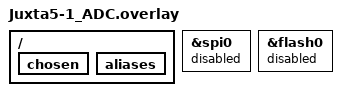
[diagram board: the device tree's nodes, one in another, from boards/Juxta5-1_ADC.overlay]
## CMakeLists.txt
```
#-------------------------------------------------------------------------------
# JUXTA BLE Application
#
# Copyright (c) 2024 NeurotechHub
# SPDX-License-Identifier: Apache-2.0

cmake_minimum_required(VERSION 3.20.0)

find_package(Zephyr REQUIRED HINTS $ENV{ZEPHYR_BASE})
project(juxta_ble LANGUAGES C)

target_sources(app PRIVATE
    src/main.c
    src/ble_service.c
    src/lis2dh12.c
)

# Add include directories for our libraries
target_include_directories(app PRIVATE 
    ../../lib/juxta_vitals_nrf52/include
    ../../lib/juxta_framfs/include
    ../../lib/juxta_fram/include
    ../../lib/lisd2h12
)

# Add library source files directly
target_sources(app PRIVATE 
    ../../lib/juxta_vitals_nrf52/src/vitals.c
    ../../lib/juxta_framfs/src/framfs.c
    ../../lib/juxta_fram/src/fram.c
    ../../lib/lisd2h12/lis2dh12_reg.c
) 
```

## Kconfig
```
# JUXTA BLE Application Configuration
#
# Copyright (c) 2024 NeurotechHub
# SPDX-License-Identifier: Apache-2.0

menu "JUXTA BLE Application"

config JUXTA_BLE_RANDOMIZATION
	bool "Enable randomization for BLE operations"
	default y
	help
	  Enable randomization for BLE advertising and scanning intervals
	  to reduce collision probability in dense deployments.

config JUXTA_BLE_MOTION_GATING
	bool "Enable motion-based BLE gating"
	default y
	help
	  Enable motion-based gating that adjusts BLE intervals based on
	  motion activity to save power.

endmenu

# Include Zephyr Kconfig
source "Kconfig.zephyr"

# Include library Kconfig files
rsource "../../lib/juxta_vitals_nrf52/Kconfig"
rsource "../../lib/juxta_fram/Kconfig"
rsource "../../lib/juxta_framfs/Kconfig" 
```

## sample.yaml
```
# Configuration file for nRF Connect SDK and testing tools
sample:
  description: Juxta BLE Application with LED Control
  name: juxta-ble
common:
  build_only: true
  integration_platforms:
    - nrf52dk_nrf52832
tests:
  app.default: {}
```

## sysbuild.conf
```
# Enable MCUboot for testing minimal configuration
SB_CONFIG_BOOTLOADER_MCUBOOT=y
```

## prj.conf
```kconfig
# Basic Bluetooth configuration - using observer architecture
CONFIG_BT=y
CONFIG_BT_OBSERVER=y
CONFIG_BT_PERIPHERAL=y
CONFIG_BT_DEVICE_NAME="JX_CONNECT"
CONFIG_BT_DEVICE_NAME_DYNAMIC=y
CONFIG_BT_MAX_CONN=1

# Enable maximum BLE GATT MTU for efficient file transfer.
# Actual ATT_MTU is negotiated at runtime by the peer (e.g., mobile app).
# NOTE: ACL buffers must be larger than L2CAP MTU to accommodate ATT headers
# Conservative approach: Use smaller buffers to avoid memory issues
CONFIG_BT_L2CAP_TX_MTU=247
CONFIG_BT_BUF_ACL_RX_SIZE=251
CONFIG_BT_BUF_ACL_TX_SIZE=251

# Additional BLE stack configuration for stability
CONFIG_BT_CTLR=y
CONFIG_BT_CTLR_ADV_EXT=n
CONFIG_BT_CTLR_SCAN_REQ_NOTIFY=n
CONFIG_BT_CTLR_SCAN_REQ_RSSI=n
CONFIG_BT_CTLR_ADV_INDICATION=n

# CONFIG_BT_CTLR_TX_PWR_PLUS_4=y
# CONFIG_BT_CTLR_TX_PWR_MINUS_8=y

# Counter API for nRF52 - DISABLED due to BLE conflict
# CONFIG_COUNTER=y
# CONFIG_NRFX_RTC0=y

# Random number generation
CONFIG_ENTROPY_GENERATOR=y

# RTT Configuration for debugging
CONFIG_USE_SEGGER_RTT=y
CONFIG_RTT_CONSOLE=y
CONFIG_SEGGER_RTT_BUFFER_SIZE_UP=8192
CONFIG_SEGGER_RTT_BUFFER_SIZE_DOWN=32

# Memory settings (increased for stability)
CONFIG_SYSTEM_WORKQUEUE_STACK_SIZE=2048
CONFIG_MAIN_STACK_SIZE=2048
CONFIG_ISR_STACK_SIZE=2048
CONFIG_BT_RX_STACK_SIZE=2048
CONFIG_BT_HCI_TX_STACK_SIZE=1536

# Minimal Bluetooth features
CONFIG_BT_SMP=n
CONFIG_BT_SIGNING=n
CONFIG_BT_ATT_PREPARE_COUNT=0
CONFIG_BT_PRIVACY=n
CONFIG_BT_SETTINGS=n
CONFIG_BT_BUF_EVT_RX_COUNT=2
CONFIG_BT_BUF_EVT_DISCARDABLE_COUNT=2

# Basic logging
CONFIG_LOG=y
CONFIG_LOG_DEFAULT_LEVEL=3
CONFIG_CONSOLE=y
CONFIG_LOG_BACKEND_RTT=y

# Enable drivers needed by vitals library and future FRAM integration
CONFIG_SPI=y
CONFIG_SPI_NRFX=y
CONFIG_ADC=y
CONFIG_ADC_ASYNC=y

# LIS2DH12 Accelerometer support - using custom driver
# CONFIG_SENSOR=y  # Disabled - using custom LIS2DH12 driver
# CONFIG_LIS2DH=y  # Disabled - using custom LIS2DH12 driver
# CONFIG_SPI_LOG_LEVEL_DBG=y
# CONFIG_SENSOR_LOG_LEVEL_DBG=y

# JUXTA Libraries
CONFIG_JUXTA_VITALS_NRF52=y
CONFIG_JUXTA_FRAM=y
CONFIG_JUXTA_FRAMFS=y

# Disable unused drivers
CONFIG_I2C=n

# Compiler optimizations
CONFIG_SIZE_OPTIMIZATIONS=y
CONFIG_COMPILER_OPT="-Os"

# Reduce kernel features
# CONFIG_MINIMAL_LIBC=y 
CONFIG_NEWLIB_LIBC=y
CONFIG_NEWLIB_LIBC_FLOAT_PRINTF=y
CONFIG_NEWLIB_LIBC_FLOAT_SCANF=y 

# Enable better fault context and debugging
CONFIG_DEBUG_THREAD_INFO=y
CONFIG_ASSERT=y 

CONFIG_THREAD_STACK_INFO=y
CONFIG_HW_STACK_PROTECTION=y

# Watchdog timer for system reliability
CONFIG_WATCHDOG=y
# Driver will be selected automatically for nRF; keep this if needed in this NCS version
CONFIG_WDT_NRFX=y

# SMP/MCUmgr over BLE (no MCUboot yet) per SMP.md
CONFIG_SETTINGS=y
CONFIG_BT_SETTINGS=y

CONFIG_MCUMGR=y
CONFIG_MCUMGR_TRANSPORT_BT=y
CONFIG_MCUMGR_GRP_IMG=y
CONFIG_MCUMGR_GRP_OS=y
CONFIG_IMG_MANAGER=y
CONFIG_STREAM_FLASH=y
CONFIG_ZCBOR=y
CONFIG_FLASH=y
CONFIG_FLASH_MAP=y
CONFIG_PARTITION_MANAGER_ENABLED=y

# Enable MCUboot bootloader with Partition Manager (per SMP.md)
CONFIG_BOOTLOADER_MCUBOOT=y

# Pull in Nordic sample DFU defaults to resolve upload area and related settings
CONFIG_NCS_SAMPLE_MCUMGR_BT_OTA_DFU=y

CONFIG_NRFX_SAADC=y
CONFIG_NRFX_TIMER1=y
CONFIG_NRFX_PPI=y

# Power Management Configuration
CONFIG_PM=y
CONFIG_PM_DEVICE=y
CONFIG_PM_DEVICE_RUNTIME=y

# Note: The brownout threshold is configured at the hardware level
# through the POWER module registers in main.c runtime configuration.
```

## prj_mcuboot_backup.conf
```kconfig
# Basic Bluetooth configuration - using observer architecture
CONFIG_BT=y
CONFIG_BT_OBSERVER=y
CONFIG_BT_PERIPHERAL=y
CONFIG_BT_DEVICE_NAME="JX_CONNECT"
CONFIG_BT_DEVICE_NAME_DYNAMIC=n
CONFIG_BT_MAX_CONN=1

# Enable maximum BLE GATT MTU (247 bytes) for efficient file transfer.
# Actual ATT_MTU is negotiated at runtime by the peer (e.g., mobile app).
CONFIG_BT_L2CAP_TX_MTU=247
CONFIG_BT_BUF_ACL_RX_SIZE=251
CONFIG_BT_BUF_ACL_TX_SIZE=251

# Additional BLE stack configuration for stability
# CONFIG_BT_CTLR=y  # Deprecated - controller is auto-selected
CONFIG_BT_CTLR_ADV_EXT=n
CONFIG_BT_CTLR_SCAN_REQ_NOTIFY=n
CONFIG_BT_CTLR_SCAN_REQ_RSSI=n
CONFIG_BT_CTLR_ADV_INDICATION=n

# Enable maximum BLE transmit power (+4 dBm) for extended range
CONFIG_BT_CTLR_TX_PWR_PLUS_4=y

# Counter API for nRF52 - DISABLED due to BLE conflict
# CONFIG_COUNTER=y
# CONFIG_NRFX_RTC0=y

# Random number generation
CONFIG_ENTROPY_GENERATOR=y

# RTT Configuration for debugging
CONFIG_USE_SEGGER_RTT=y
CONFIG_RTT_CONSOLE=y
CONFIG_SEGGER_RTT_BUFFER_SIZE_UP=8192
CONFIG_SEGGER_RTT_BUFFER_SIZE_DOWN=32

# Memory settings (increased for stability)
CONFIG_SYSTEM_WORKQUEUE_STACK_SIZE=2048
CONFIG_MAIN_STACK_SIZE=2048
CONFIG_ISR_STACK_SIZE=2048
CONFIG_BT_RX_STACK_SIZE=2048
CONFIG_BT_HCI_TX_STACK_SIZE=1536

# Minimal Bluetooth features
CONFIG_BT_SMP=n
CONFIG_BT_SIGNING=n
CONFIG_BT_ATT_PREPARE_COUNT=0
CONFIG_BT_PRIVACY=n
CONFIG_BT_SETTINGS=n
CONFIG_BT_BUF_EVT_RX_COUNT=2
CONFIG_BT_BUF_EVT_DISCARDABLE_COUNT=2

# Basic logging
CONFIG_LOG=y
CONFIG_LOG_DEFAULT_LEVEL=3
CONFIG_CONSOLE=y
CONFIG_LOG_BACKEND_RTT=y

# Enable drivers needed by vitals library and future FRAM integration
CONFIG_SPI=y
CONFIG_SPI_NRFX=y
CONFIG_ADC=y

# LIS2DH12 Accelerometer support - using custom driver
# CONFIG_SENSOR=y  # Disabled - using custom LIS2DH12 driver
# CONFIG_LIS2DH=y  # Disabled - using custom LIS2DH12 driver
# CONFIG_SPI_LOG_LEVEL_DBG=y
# CONFIG_SENSOR_LOG_LEVEL_DBG=y

# JUXTA Libraries
CONFIG_JUXTA_VITALS_NRF52=y
CONFIG_JUXTA_FRAM=y
CONFIG_JUXTA_FRAMFS=y

# Disable unused drivers
CONFIG_I2C=n

# Compiler optimizations
CONFIG_SIZE_OPTIMIZATIONS=y
CONFIG_COMPILER_OPT="-Os"

# Reduce kernel features
# CONFIG_MINIMAL_LIBC=y 
CONFIG_NEWLIB_LIBC=y
CONFIG_NEWLIB_LIBC_FLOAT_PRINTF=y
CONFIG_NEWLIB_LIBC_FLOAT_SCANF=y 

# Enable better fault context and debugging
CONFIG_DEBUG_THREAD_INFO=y
CONFIG_ASSERT=y 

CONFIG_THREAD_STACK_INFO=y
CONFIG_HW_STACK_PROTECTION=y

# Watchdog timer for system reliability
CONFIG_WATCHDOG=y
# Driver will be selected automatically for nRF; keep this if needed in this NCS version
CONFIG_WDT_NRFX=y

# SMP/MCUmgr over BLE (no MCUboot yet) per SMP.md
CONFIG_SETTINGS=y
CONFIG_BT_SETTINGS=y

CONFIG_MCUMGR=y
CONFIG_MCUMGR_TRANSPORT_BT=y
CONFIG_MCUMGR_GRP_IMG=y
CONFIG_MCUMGR_GRP_OS=y
CONFIG_IMG_MANAGER=y
CONFIG_STREAM_FLASH=y
CONFIG_ZCBOR=y
CONFIG_FLASH=y
CONFIG_FLASH_MAP=y

# Enable MCUboot bootloader with fixed partitions
CONFIG_BOOTLOADER_MCUBOOT=y

# Ensure proper vector table relocation for MCUboot slot0 (0x10000)
CONFIG_USE_DT_CODE_PARTITION=y

# Pull in Nordic sample DFU defaults to resolve upload area and related settings
CONFIG_NCS_SAMPLE_MCUMGR_BT_OTA_DFU=y
```

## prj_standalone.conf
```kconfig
# Temporary standalone test - copy of prj.conf but without MCUboot
# Basic Bluetooth configuration - using observer architecture
CONFIG_BT=y
CONFIG_BT_OBSERVER=y
CONFIG_BT_PERIPHERAL=y
CONFIG_BT_DEVICE_NAME="JX_CONNECT"
CONFIG_BT_DEVICE_NAME_DYNAMIC=n
CONFIG_BT_MAX_CONN=1

# Enable maximum BLE GATT MTU (247 bytes) for efficient file transfer.
# Actual ATT_MTU is negotiated at runtime by the peer (e.g., mobile app).
CONFIG_BT_L2CAP_TX_MTU=247
CONFIG_BT_BUF_ACL_RX_SIZE=251
CONFIG_BT_BUF_ACL_TX_SIZE=251

# Additional BLE stack configuration for stability
# CONFIG_BT_CTLR=y  # Deprecated - controller is auto-selected
CONFIG_BT_CTLR_ADV_EXT=n
CONFIG_BT_CTLR_SCAN_REQ_NOTIFY=n
CONFIG_BT_CTLR_SCAN_REQ_RSSI=n
CONFIG_BT_CTLR_ADV_INDICATION=n

# Enable maximum BLE transmit power (+4 dBm) for extended range
CONFIG_BT_CTLR_TX_PWR_PLUS_4=y

# Counter API for nRF52 - DISABLED due to BLE conflict
# CONFIG_COUNTER=y
# CONFIG_NRFX_RTC0=y

# Random number generation
CONFIG_ENTROPY_GENERATOR=y

# RTT Configuration for debugging
CONFIG_USE_SEGGER_RTT=y
CONFIG_RTT_CONSOLE=y
CONFIG_SEGGER_RTT_BUFFER_SIZE_UP=8192
CONFIG_SEGGER_RTT_BUFFER_SIZE_DOWN=32

# Memory settings (increased for stability)
CONFIG_SYSTEM_WORKQUEUE_STACK_SIZE=2048
CONFIG_MAIN_STACK_SIZE=2048
CONFIG_ISR_STACK_SIZE=2048
CONFIG_BT_RX_STACK_SIZE=2048
CONFIG_BT_HCI_TX_STACK_SIZE=1536

# Minimal Bluetooth features
CONFIG_BT_SMP=n
CONFIG_BT_SIGNING=n
CONFIG_BT_ATT_PREPARE_COUNT=0
CONFIG_BT_PRIVACY=n
CONFIG_BT_SETTINGS=n
CONFIG_BT_BUF_EVT_RX_COUNT=2
CONFIG_BT_BUF_EVT_DISCARDABLE_COUNT=2

# Basic logging
CONFIG_LOG=y
CONFIG_LOG_DEFAULT_LEVEL=3
CONFIG_CONSOLE=y
CONFIG_LOG_BACKEND_RTT=y

# Enable drivers needed by vitals library and future FRAM integration
CONFIG_SPI=y
CONFIG_SPI_NRFX=y
CONFIG_ADC=y

# JUXTA Libraries
CONFIG_JUXTA_VITALS_NRF52=y
CONFIG_JUXTA_FRAM=y
CONFIG_JUXTA_FRAMFS=y

# Disable unused drivers
CONFIG_I2C=n

# Compiler optimizations
CONFIG_SIZE_OPTIMIZATIONS=y
CONFIG_COMPILER_OPT="-Os"

# Reduce kernel features
# CONFIG_MINIMAL_LIBC=y 
CONFIG_NEWLIB_LIBC=y
CONFIG_NEWLIB_LIBC_FLOAT_PRINTF=y
CONFIG_NEWLIB_LIBC_FLOAT_SCANF=y 

# Enable better fault context and debugging
CONFIG_DEBUG_THREAD_INFO=y
CONFIG_ASSERT=y 

CONFIG_THREAD_STACK_INFO=y
CONFIG_HW_STACK_PROTECTION=y

# Watchdog timer for system reliability
CONFIG_WATCHDOG=y
# Driver will be selected automatically for nRF; keep this if needed in this NCS version
CONFIG_WDT_NRFX=y

# NO MCUboot - standalone test
# CONFIG_BOOTLOADER_MCUBOOT=n
```

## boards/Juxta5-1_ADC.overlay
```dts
/*
 * Device tree overlay for Juxta BLE application
 * Disables SPI/FRAM functionality since this app only needs BLE and LED
 */

/ {
    chosen {
        /delete-property/ zephyr,eeprom;
    };

    aliases {
        /delete-property/ spi-fram;
    };
};

&spi0 {
    status = "disabled";

    /delete-node/ fram@0;
};

&flash0 {
    status = "disabled";
}; 
```

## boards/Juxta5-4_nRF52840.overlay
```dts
/*
 * Board overlay for Juxta5-4_nRF52840 for BLE application
 * This file configures the board for BLE and RTC functionality
 */

/ {
    aliases {
        rtc = &rtc0;
    };
};

/* Configure RTC for timestamp management */
&rtc0 {
    status = "okay";
    clock-frequency = <32768>;
    interrupt-parent = <&nvic>;
    interrupts = <11 NRF_DEFAULT_IRQ_PRIORITY>;
}; 
```

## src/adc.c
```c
/*
 * JUXTA ADC Module Implementation
 * Provides functionality for reading differential ADC measurements
 *
 * Copyright (c) 2025 NeurotechHub
 * SPDX-License-Identifier: Apache-2.0
 */

#include "adc.h"
#include <zephyr/drivers/adc.h>
#include <zephyr/logging/log.h>
#include <zephyr/devicetree.h>
#include <zephyr/irq.h>
#include <string.h>
#include <math.h>
#include <hal/nrf_rtc.h>
#include <hal/nrf_saadc.h>

LOG_MODULE_REGISTER(juxta_adc, LOG_LEVEL_INF);

/* ADC device and configuration */
static const struct device *adc_dev;
static struct adc_channel_cfg adc_cfg;
static struct adc_sequence adc_seq;
static int16_t adc_sample_buffer;
static bool adc_initialized = false;

int juxta_adc_init(void)
{
    int ret;

    /* Get ADC device */
    adc_dev = DEVICE_DT_GET(DT_NODELABEL(adc));
    if (!device_is_ready(adc_dev))
    {
        LOG_ERR("ADC device not ready");
        return -ENODEV;
    }

    LOG_INF("ADC device ready: %s", adc_dev->name);

    /* Configure ADC channel 0 for differential measurement (AIN0/AIN1) */
    memset(&adc_cfg, 0, sizeof(adc_cfg));
    adc_cfg.gain = ADC_GAIN_1_6;
    adc_cfg.reference = ADC_REF_INTERNAL;
    adc_cfg.acquisition_time = ADC_ACQ_TIME_DEFAULT;
    adc_cfg.channel_id = 0;                                     /* Use channel 0 for differential measurement */
    adc_cfg.input_positive = SAADC_CH_PSELP_PSELP_AnalogInput1; /* P0.03 */
    adc_cfg.input_negative = SAADC_CH_PSELN_PSELN_AnalogInput0; /* P0.02 */
    adc_cfg.differential = 1;

    ret = adc_channel_setup(adc_dev, &adc_cfg);
    if (ret != 0)
    {
        LOG_ERR("Failed to setup ADC channel: %d", ret);
        return ret;
    }

    /* Configure ADC sequence */
    memset(&adc_seq, 0, sizeof(adc_seq));
    adc_seq.channels = BIT(0);
    adc_seq.buffer = &adc_sample_buffer;
    adc_seq.buffer_size = sizeof(adc_sample_buffer);
    adc_seq.resolution = 12;
    adc_seq.oversampling = 0; /* Disable oversampling for maximum speed */
    adc_seq.calibrate = true;

    LOG_INF("ADC differential measurement configured:");
    LOG_INF("  Channel: %d", adc_cfg.channel_id);
    LOG_INF("  Input: AIN1 (P0.03) - AIN0 (P0.02)");
    LOG_INF("  Resolution: %d bits", adc_seq.resolution);
    LOG_INF("  Oversampling: %d", adc_seq.oversampling);
    LOG_INF("  Gain: 1/6");

    adc_initialized = true;
    return 0;
}

int juxta_adc_read_differential(int32_t *value_mv)
{
    int ret;

    if (!adc_initialized || !adc_dev)
    {
        LOG_ERR("ADC not initialized");
        return -ENODEV;
    }

    if (!value_mv)
    {
        LOG_ERR("Invalid parameter: value_mv is NULL");
        return -EINVAL;
    }

    /* Read ADC value */
    ret = adc_read(adc_dev, &adc_seq);
    if (ret != 0)
    {
        LOG_ERR("ADC read failed: %d", ret);
        return ret;
    }

    LOG_DBG("ADC raw value: %d", adc_sample_buffer);

    /* Convert to millivolts */
    *value_mv = adc_sample_buffer;
    ret = adc_raw_to_millivolts(adc_ref_internal(adc_dev),
                                adc_cfg.gain,
                                adc_seq.resolution,
                                value_mv);
    if (ret != 0)
    {
        LOG_ERR("ADC conversion failed: %d", ret);
        return ret;
    }

    LOG_DBG("ADC differential reading: %d mV (raw: %d)", *value_mv, adc_sample_buffer);
    return 0;
}

bool juxta_adc_is_ready(void)
{
    return adc_initialized && device_is_ready(adc_dev);
}

int juxta_adc_burst_sample(int32_t *samples, uint32_t max_samples,
                           uint32_t *actual_samples, uint32_t *duration_us)
{
    if (!adc_initialized || !adc_dev)
    {
        return -ENODEV;
    }

    if (!samples || !actual_samples || !duration_us)
    {
        return -EINVAL;
    }

    if (max_samples < 100)
    {
        return -EINVAL;
    }

    /* Start timing using RTC0 counter (32kHz clock) */
    uint32_t start_ticks = NRF_RTC0->COUNTER;
    uint32_t sample_count = 0;

    /* Debug: Log RTC0 configuration for timing verification */
    LOG_DBG("🔍 RTC0 Debug: PRESCALER=0x%08X, COUNTER=%u, start_ticks=%u",
            (unsigned)NRF_RTC0->PRESCALER, (unsigned)NRF_RTC0->COUNTER, (unsigned)start_ticks);

    /* Use optimized batch sampling to avoid per-sample overhead */
    /* Configure sequence for burst sampling */
    static int16_t burst_buffer[500]; /* Static buffer for raw ADC values */

    struct adc_sequence burst_seq = {
        .channels = BIT(0),
        .buffer = burst_buffer,
        .buffer_size = sizeof(burst_buffer),
        .resolution = 12,
        .oversampling = 0, /* Disable oversampling for maximum speed */
        .calibrate = false /* Disable per-read calibration for speed */
    };

    /* Disable interrupts during critical sampling for consistent timing */
    unsigned int key = irq_lock();

    /* Perform optimized burst sampling with minimal overhead */
    for (uint32_t i = 0; i < max_samples; i++)
    {
        /* Direct ADC read without function call overhead */
        int ret = adc_read(adc_dev, &burst_seq);

        if (ret == 0)
        {
            /* Convert raw ADC value to millivolts */
            int32_t voltage_mv = burst_buffer[0];
            ret = adc_raw_to_millivolts(adc_ref_internal(adc_dev),
                                        adc_cfg.gain,
                                        burst_seq.resolution,
                                        &voltage_mv);

            samples[sample_count] = (ret == 0) ? voltage_mv : 0;
            sample_count++;
        }
        else
        {
            /* Use previous sample value if ADC read fails */
            if (sample_count > 0)
            {
                samples[sample_count] = samples[sample_count - 1];
            }
            else
            {
                samples[sample_count] = 0; /* Default to 0 if no previous sample */
            }
            sample_count++;
        }

        /* No artificial delay - let ADC conversion time be the limiting factor */
    }

    /* Re-enable interrupts */
    irq_unlock(key);

    /* End timing */
    uint32_t end_ticks = NRF_RTC0->COUNTER;

    /* Handle RTC0 rollover (24-bit counter: 0xFFFFFF + 1 = 0x000000) */
    uint32_t duration_ticks;
    if (end_ticks >= start_ticks)
    {
        duration_ticks = end_ticks - start_ticks;
    }
    else
    {
        /* Rollover occurred during sampling */
        duration_ticks = (0x1000000 - start_ticks) + end_ticks;
    }

    /* Calculate actual duration with improved precision */
    *actual_samples = sample_count; /* Always equals max_samples now */

    /* Use 64-bit arithmetic to avoid overflow and improve precision */
    /* RTC0 runs at exactly 32768 Hz, so each tick = 1000000/32768 = 30.517578125 μs */
    uint64_t duration_us_64 = ((uint64_t)duration_ticks * 1000000ULL) / 32768ULL;
    *duration_us = (uint32_t)duration_us_64; /* Convert ticks to microseconds */

    LOG_DBG("📊 ADC burst completed: requested=%u, actual=%u, duration=%u us (ticks=%u, start=%u, end=%u)",
            (unsigned)max_samples, (unsigned)sample_count, (unsigned)*duration_us,
            (unsigned)duration_ticks, (unsigned)start_ticks, (unsigned)end_ticks);

    return 0;
}

/**
 * @brief Test function to verify ADC timing accuracy
 *
 * This function can be called during development to verify that the
 * duration calculation matches expected timing based on sample count
 * and known ADC conversion characteristics.
 *
 * @param expected_samples Number of samples to test with
 * @return 0 on success, negative error code on failure
 */
int juxta_adc_test_timing(uint32_t expected_samples)
{
    if (expected_samples < 200 || expected_samples > 2000)
    {
        return -EINVAL;
    }

    LOG_INF("🧪 Testing ADC timing accuracy with %u samples", (unsigned)expected_samples);

    /* Use static buffer to avoid k_malloc dependency */
    static int32_t test_samples[2000];

    uint32_t actual_samples, duration_us;
    int ret = juxta_adc_burst_sample(test_samples, expected_samples, &actual_samples, &duration_us);

    if (ret == 0)
    {
        // Calculate expected timing based on maximum speed ADC characteristics
        // Each sample: ~2-3μs ADC conversion (no artificial delay) = ~3μs per sample (target)
        uint32_t expected_duration_us = expected_samples * 3U;
        int32_t timing_error = (int32_t)duration_us - (int32_t)expected_duration_us;
        int32_t error_percent_x100 = (timing_error * 10000) / (int32_t)expected_duration_us; /* Error % * 100 */

        LOG_INF("🧪 Timing test results:");
        LOG_INF("  Expected: %u samples in ~%u μs", (unsigned)expected_samples, (unsigned)expected_duration_us);
        LOG_INF("  Actual:   %u samples in %u μs", (unsigned)actual_samples, (unsigned)duration_us);
        LOG_INF("  Error:    %d μs (%d.%02d%%)", timing_error, error_percent_x100 / 100, (error_percent_x100 % 100));

        if ((timing_error < 0 ? -timing_error : timing_error) > (int32_t)(expected_duration_us / 10U))
        { // >10% error
            LOG_WRN("⚠️ Timing error exceeds 10%% - duration calculation may be inaccurate");
        }
        else
        {
            LOG_INF("✅ Timing accuracy within acceptable range");
        }
    }

    return ret;
}

/**
 * @brief Test RTC0 frequency accuracy using k_sleep() as reference
 *
 * This function tests if RTC0 is actually running at 32768 Hz by comparing
 * its tick count against a known k_sleep() delay.
 *
 * @return 0 on success, negative error code on failure
 */
int juxta_adc_test_rtc0_frequency(void)
{
    LOG_INF("🕐 Testing RTC0 frequency accuracy...");

    /* Log RTC0 configuration */
    LOG_INF("🕐 RTC0 PRESCALER: 0x%08X (should be 0 for 32768Hz)", (unsigned)NRF_RTC0->PRESCALER);
    LOG_INF("🕐 RTC0 running: %s", (NRF_RTC0->TASKS_START) ? "yes" : "unknown");

    /* Test RTC0 frequency using k_sleep as reference */
    uint32_t start_ticks = NRF_RTC0->COUNTER;
    uint32_t start_uptime = k_uptime_get_32();

    LOG_INF("🕐 Starting frequency test: RTC0=%u, uptime=%u ms", start_ticks, start_uptime);

    /* Wait exactly 1 second using k_sleep */
    k_sleep(K_MSEC(1000));

    uint32_t end_ticks = NRF_RTC0->COUNTER;
    uint32_t end_uptime = k_uptime_get_32();

    /* Handle potential RTC0 rollover */
    uint32_t rtc_ticks_elapsed;
    if (end_ticks >= start_ticks)
    {
        rtc_ticks_elapsed = end_ticks - start_ticks;
    }
    else
    {
        rtc_ticks_elapsed = (0x1000000 - start_ticks) + end_ticks;
    }

    uint32_t uptime_elapsed = end_uptime - start_uptime;

    /* Calculate actual RTC0 frequency */
    uint32_t measured_rtc_freq = rtc_ticks_elapsed; /* Should be ~32768 for 1 second */
    float freq_error_percent = ((float)measured_rtc_freq - 32768.0f) / 32768.0f * 100.0f;

    LOG_INF("🕐 Frequency test results:");
    LOG_INF("  k_sleep elapsed: %u ms", uptime_elapsed);
    LOG_INF("  RTC0 ticks elapsed: %u", rtc_ticks_elapsed);
    LOG_INF("  Measured RTC0 freq: %u Hz (expected: 32768 Hz)", measured_rtc_freq);
    LOG_INF("  Frequency error: %.2f%%", (double)freq_error_percent);

    if (uptime_elapsed < 950 || uptime_elapsed > 1050)
    {
        LOG_WRN("⚠️ k_sleep timing is off - system timing issue");
    }

    if (fabsf(freq_error_percent) > 5.0f)
    {
        LOG_ERR("❌ RTC0 frequency error > 5%% - this explains ADC duration inaccuracy!");
        return -1;
    }
    else if (fabsf(freq_error_percent) > 1.0f)
    {
        LOG_WRN("⚠️ RTC0 frequency error > 1%% - minor timing inaccuracy");
    }
    else
    {
        LOG_INF("✅ RTC0 frequency within acceptable range");
    }

    return 0;
}
```

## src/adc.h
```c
/*
 * JUXTA ADC Module Header
 * Provides interface for reading differential ADC measurements
 *
 * Copyright (c) 2025 NeurotechHub
 * SPDX-License-Identifier: Apache-2.0
 */

#ifndef JUXTA_ADC_H_
#define JUXTA_ADC_H_

#include <zephyr/kernel.h>
#include <stdint.h>

#ifdef __cplusplus
extern "C"
{
#endif

    /**
     * @brief Initialize the ADC module for differential measurements
     *
     * This function sets up the ADC for reading differential measurements
     * on AIN0 (P0.02) and AIN1 (P0.03) using channel 0.
     *
     * @return 0 on success, negative error code on failure
     */
    int juxta_adc_init(void);

    /**
     * @brief Read a differential ADC measurement
     *
     * Reads the differential voltage between AIN0 (P0.02) and AIN1 (P0.03).
     * The measurement uses the configuration from the device tree:
     * - 12-bit resolution
     * - 8x oversampling
     * - 1/6 gain
     * - Internal reference
     *
     * @param value_mv Pointer to store the measurement result in millivolts
     * @return 0 on success, negative error code on failure
     */
    int juxta_adc_read_differential(int32_t *value_mv);

    /**
     * @brief Check if ADC module is initialized and ready
     *
     * @return true if ADC is ready, false otherwise
     */
    bool juxta_adc_is_ready(void);

    /**
     * @brief Perform a burst of ADC samples with precise timing
     *
     * Performs continuous ADC sampling for approximately 2ms with ~10μs intervals.
     * Uses RTC0 counter for precise timing measurement.
     *
     * @param samples Buffer to store ADC samples (must be at least 200 samples)
     * @param max_samples Maximum number of samples to store
     * @param actual_samples Pointer to store actual number of samples taken
     * @param duration_us Pointer to store actual duration in microseconds
     * @return 0 on success, negative error code on failure
     */
    int juxta_adc_burst_sample(int32_t *samples, uint32_t max_samples,
                               uint32_t *actual_samples, uint32_t *duration_us);

    /**
     * @brief Test function to verify ADC timing accuracy
     *
     * This function can be called during development to verify that the
     * duration calculation matches expected timing based on sample count
     * and known ADC conversion characteristics.
     *
     * @param expected_samples Number of samples to test with (200-2000)
     * @return 0 on success, negative error code on failure
     */
    int juxta_adc_test_timing(uint32_t expected_samples);

    /**
     * @brief Test RTC0 frequency accuracy using k_sleep() as reference
     *
     * This function tests if RTC0 is actually running at 32768 Hz by comparing
     * its tick count against a known k_sleep() delay.
     *
     * @return 0 on success, negative error code on failure
     */
    int juxta_adc_test_rtc0_frequency(void);

#ifdef __cplusplus
}
#endif

#endif /* JUXTA_ADC_H_ */
```

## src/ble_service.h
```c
/*
 * JUXTA BLE Service Header
 * Defines BLE service and characteristics for JUXTA Hublink protocol
 *
 * Copyright (c) 2025 NeurotechHub
 * SPDX-License-Identifier: Apache-2.0
 */

#ifndef JUXTA_BLE_SERVICE_H_
#define JUXTA_BLE_SERVICE_H_

#include <zephyr/kernel.h>
#include <stdbool.h>
#include <zephyr/bluetooth/uuid.h>
#include <zephyr/bluetooth/conn.h>
#include "juxta_framfs/framfs.h"

/* Forward declaration for framfs context */
struct juxta_framfs_context;

/* Forward declaration for vitals context */
struct juxta_vitals_ctx;

#ifdef __cplusplus
extern "C"
{
#endif

/* Hublink Service UUID: 57617368-5501-0001-8000-00805f9b34fb */
#define JUXTA_HUBLINK_SERVICE_UUID 0xFB, 0x34, 0x9B, 0x5F, 0x80, 0x00, 0x00, 0x80, \
                                   0x01, 0x00, 0x01, 0x55, 0x68, 0x73, 0x61, 0x57

/* Node Characteristic UUID: 57617368-5505-0001-8000-00805f9b34fb (READ) */
#define JUXTA_NODE_CHAR_UUID 0xFB, 0x34, 0x9B, 0x5F, 0x80, 0x00, 0x00, 0x80, \
                             0x01, 0x00, 0x05, 0x55, 0x68, 0x73, 0x61, 0x57

/* Gateway Characteristic UUID: 57617368-5504-0001-8000-00805f9b34fb (WRITE) */
#define JUXTA_GATEWAY_CHAR_UUID 0xFB, 0x34, 0x9B, 0x5F, 0x80, 0x00, 0x00, 0x80, \
                                0x01, 0x00, 0x04, 0x55, 0x68, 0x73, 0x61, 0x57

/* Filename Characteristic UUID: 57617368-5502-0001-8000-00805f9b34fb (READ/WRITE/INDICATE) */
#define JUXTA_FILENAME_CHAR_UUID 0xFB, 0x34, 0x9B, 0x5F, 0x80, 0x00, 0x00, 0x80, \
                                 0x01, 0x00, 0x02, 0x55, 0x68, 0x73, 0x61, 0x57

/* File Transfer Characteristic UUID: 57617368-5503-0001-8000-00805f9b34fb (READ/INDICATE) */
#define JUXTA_FILE_TRANSFER_CHAR_UUID 0xFB, 0x34, 0x9B, 0x5F, 0x80, 0x00, 0x00, 0x80, \
                                      0x01, 0x00, 0x03, 0x55, 0x68, 0x73, 0x61, 0x57

#define BT_UUID_JUXTA_HUBLINK_SERVICE BT_UUID_DECLARE_128(JUXTA_HUBLINK_SERVICE_UUID)
#define BT_UUID_JUXTA_NODE_CHAR BT_UUID_DECLARE_128(JUXTA_NODE_CHAR_UUID)
#define BT_UUID_JUXTA_GATEWAY_CHAR BT_UUID_DECLARE_128(JUXTA_GATEWAY_CHAR_UUID)
#define BT_UUID_JUXTA_FILENAME_CHAR BT_UUID_DECLARE_128(JUXTA_FILENAME_CHAR_UUID)
#define BT_UUID_JUXTA_FILE_TRANSFER_CHAR BT_UUID_DECLARE_128(JUXTA_FILE_TRANSFER_CHAR_UUID)

/* Firmware version */
#define JUXTA_FIRMWARE_VERSION "1.0.1"

/* Maximum JSON response sizes */
#define JUXTA_NODE_RESPONSE_MAX_SIZE 256
#define JUXTA_GATEWAY_COMMAND_MAX_SIZE 256
#define JUXTA_FILENAME_MAX_SIZE 64
#define JUXTA_FILE_TRANSFER_CHUNK_SIZE 1024

    /**
     * @brief Initialize the JUXTA Hublink BLE service
     *
     * This function registers the JUXTA Hublink BLE service and its characteristics
     * with the Bluetooth stack.
     *
     * @return 0 on success, negative error code on failure
     */
    int juxta_ble_service_init(void);

    /**
     * @brief Get the current device ID (JX_XXXXXX format)
     *
     * @param device_id Buffer to store device ID (must be at least 10 bytes)
     * @return 0 on success, negative error code on failure
     */
    int juxta_ble_get_device_id(char *device_id);

    /**
     * @brief Set the framfs context for user settings access
     *
     * @param ctx Initialized framfs context
     */
    void juxta_ble_set_framfs_context(struct juxta_framfs_context *ctx);

    /**
     * @brief Set the time-aware framfs context for file operations
     *
     * @param ctx Initialized time-aware framfs context
     */
    void juxta_ble_set_time_aware_framfs_context(struct juxta_framfs_ctx *ctx);

    /**
     * @brief Set the vitals context for timestamp synchronization
     *
     * @param ctx Initialized vitals context
     */
    void juxta_ble_set_vitals_context(struct juxta_vitals_ctx *ctx);

    /**
     * @brief Set the watchdog channel ID for feeding during long operations
     *
     * @param channel_id Watchdog channel ID from main.c
     */
    // void juxta_ble_set_watchdog_channel(int channel_id); /* COMMENTED OUT - watchdog not hardened */

    /**
     * @brief Trigger timing update callback (called when settings change)
     *
     * This function should be implemented in main.c to handle timing updates
     */
    extern void juxta_ble_timing_update_trigger(void);

    /**
     * @brief Get current ADC sampling rate from session configuration
     * @return Current sampling rate in Hz
     */
    extern uint32_t juxta_get_adc_sampling_rate(void);

    /**
     * @brief Set ADC sampling rate in session configuration
     * @param sampling_rate_hz Sampling rate in Hz (will be clamped to 1kHz-100kHz range)
     */
    extern void juxta_set_adc_sampling_rate(uint32_t sampling_rate_hz);

    /**
     * @brief Trigger ADC configuration update when ADC settings change
     * This function should be implemented in main.c to handle ADC config updates
     */
    extern void juxta_ble_adc_config_update_trigger(void);

    /**
     * @brief Get current operating mode
     * @return Current operating mode (0xFF=undefined, 0x00=normal, 0x01=adc_only)
     */
    uint8_t juxta_get_current_operating_mode(void);

    /**
     * @brief Set current operating mode
     * @param mode Operating mode to set
     */
    void juxta_set_operating_mode(uint8_t mode);

    /**
     * @brief Get current session intervals
     * @param adv_interval Pointer to store advertising interval (can be NULL)
     * @param scan_interval Pointer to store scanning interval (can be NULL)
     */
    void juxta_get_session_intervals(uint8_t *adv_interval, uint8_t *scan_interval);

    /**
     * @brief Set current session intervals
     * @param adv_interval Advertising interval in seconds
     * @param scan_interval Scanning interval in seconds
     */
    void juxta_set_session_intervals(uint8_t adv_interval, uint8_t scan_interval);

    /**
     * @brief Get current inactivity doubler setting
     * @return true if motion-based interval doubling is enabled, false otherwise
     */
    bool juxta_get_session_inactivity_doubler_enabled(void);

    /**
     * @brief Set current inactivity doubler setting
     * @param enabled true to enable motion-based interval doubling, false to disable
     */
    void juxta_set_session_inactivity_doubler_enabled(bool enabled);

    /**
     * @brief Connection established callback
     *
     * @param conn Bluetooth connection handle
     */
    void juxta_ble_connection_established(struct bt_conn *conn);

    /**
     * @brief Connection terminated callback
     */
    void juxta_ble_connection_terminated(void);

    /**
     * @brief MTU updated callback
     *
     * @param new_mtu New MTU size after exchange
     */
    void juxta_ble_mtu_updated(uint16_t new_mtu);

    /**
     * @brief Get current service status for debugging
     *
     * @param mtu Pointer to store current MTU size
     * @param connected Pointer to store connection status
     * @param transfer_active Pointer to store file transfer status
     * @return 0 on success, negative error code on failure
     */
    int juxta_ble_get_status(uint16_t *mtu, bool *connected, bool *transfer_active);

    /**
     * @brief Test function for gateway command functionality
     *
     * This function tests timestamp synchronization and clearMemory functionality.
     * It can be called during development to verify the implementation.
     *
     * @return 0 on success, negative error code on failure
     */
    int juxta_ble_test_gateway_commands(void);

    /**
     * @brief Set datetime synchronization callback function
     *
     * This function sets a callback that will be called when datetime is synchronized.
     * Used for production flow to track when timestamp has been updated via BLE.
     *
     * @param callback Function to call when datetime is synchronized (can be NULL)
     */
    void juxta_ble_set_datetime_sync_callback(void (*callback)(void));

#ifdef __cplusplus
}
#endif

#endif /* JUXTA_BLE_SERVICE_H_ */
```

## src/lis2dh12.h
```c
/*
 * Custom LIS2DH12 Zephyr Wrapper
 *
 * Copyright (c) 2024 NeurotechHub
 * SPDX-License-Identifier: Apache-2.0
 */

#ifndef LIS2DH12_H
#define LIS2DH12_H

#include <zephyr/kernel.h>
#include <zephyr/drivers/spi.h>
#include <zephyr/drivers/gpio.h>
#include <zephyr/logging/log.h>
#include "lis2dh12_reg.h"

/* LIS2DH12 device context */
struct lis2dh12_dev
{
    const struct device *spi_dev;
    struct spi_config spi_cfg;
    struct gpio_dt_spec cs_gpio;
    struct gpio_dt_spec int_gpio;

    bool initialized;
};

/* Function prototypes */
int lis2dh12_init(struct lis2dh12_dev *dev);
int lis2dh12_read_accel(struct lis2dh12_dev *dev, float *x, float *y, float *z);
int lis2dh12_read_temperature_lowres(struct lis2dh12_dev *dev, int8_t *temperature);
int lis2dh12_configure_motion_detection(struct lis2dh12_dev *dev,
                                        uint8_t threshold, uint8_t duration);
int lis2dh12_read_device_id(struct lis2dh12_dev *dev, uint8_t *id);
bool lis2dh12_is_ready(struct lis2dh12_dev *dev);
int lis2dh12_read_int1_source(struct lis2dh12_dev *dev, uint8_t *source);
int lis2dh12_clear_int1_interrupt(struct lis2dh12_dev *dev);
int lis2dh12_reset_motion_detection(struct lis2dh12_dev *dev);
int lis2dh12_test_interrupt_clearing(struct lis2dh12_dev *dev);
int lis2dh12_analyze_interrupt_trigger(struct lis2dh12_dev *dev);

/* Motion system management functions */
int lis2dh12_init_motion_system(void);
void lis2dh12_process_motion_events(void);
bool lis2dh12_should_use_extended_intervals(void);
uint8_t lis2dh12_get_motion_count(void);
void lis2dh12_reset_motion_count(void);

/* Temperature reading function for motion system */
int lis2dh12_get_temperature(int8_t *temperature);

/* Platform functions for direct register access */
int32_t lis2dh12_platform_read(void *handle, uint8_t reg, uint8_t *data, uint16_t len);
int32_t lis2dh12_platform_write(void *handle, uint8_t reg, const uint8_t *data, uint16_t len);

#endif /* LIS2DH12_H */
```

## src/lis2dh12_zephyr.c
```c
/*
 * Custom LIS2DH12 Zephyr Wrapper Implementation
 *
 * Copyright (c) 2024 NeurotechHub
 * SPDX-License-Identifier: Apache-2.0
 */

#include "lis2dh12_zephyr.h"
#include <zephyr/sys/util.h>
#include <string.h>

LOG_MODULE_REGISTER(lis2dh12_zephyr, LOG_LEVEL_INF);

/* Global context for platform functions */
static struct lis2dh12_zephyr_dev *g_lis2dh12_dev = NULL;

/**
 * @brief Platform-specific SPI read function for STMicroelectronics library
 *
 * This function implements the required interface for the library's function pointers.
 */
int32_t lis2dh12_platform_read(void *handle, uint8_t reg, uint8_t *data, uint16_t len)
{
    /* For SPI, set read bit (bit 7) and increment bit (bit 6) for multi-byte reads */
    uint8_t tx_reg = reg | 0x80; /* Set read bit */
    if (len > 1)
    {
        tx_reg |= 0x40; /* Set increment bit for multi-byte reads */
    }

    LOG_DBG("LIS2DH READ: reg=0x%02X, tx_reg=0x%02X, len=%d", reg, tx_reg, len);

    uint8_t tx_buf[1 + len]; /* Register + dummy bytes */
    uint8_t rx_buf[1 + len]; /* Response */

    tx_buf[0] = tx_reg;
    memset(&tx_buf[1], 0x00, len); /* Dummy bytes */

    LOG_DBG("LIS2DH READ: tx_buf[0]=0x%02X, tx_buf[1]=0x%02X", tx_buf[0], tx_buf[1]);

    const struct spi_buf tx_bufs = {
        .buf = tx_buf,
        .len = sizeof(tx_buf)};
    const struct spi_buf rx_bufs = {
        .buf = rx_buf,
        .len = sizeof(rx_buf)};
    const struct spi_buf_set tx = {
        .buffers = &tx_bufs,
        .count = 1};
    const struct spi_buf_set rx = {
        .buffers = &rx_bufs,
        .count = 1};

    /* Set CS low (select device - CS is active low) */
    gpio_pin_set(g_lis2dh12_dev->cs_gpio.port, g_lis2dh12_dev->cs_gpio.pin, 0);
    k_sleep(K_USEC(10)); // Small delay for CS setup
    LOG_DBG("LIS2DH READ: CS set low (selected), starting SPI transaction");

    /* Perform SPI transaction */
    int ret = spi_transceive(g_lis2dh12_dev->spi_dev, &g_lis2dh12_dev->spi_cfg, &tx, &rx);

    /* Set CS high (deselect device - CS is active low) */
    gpio_pin_set(g_lis2dh12_dev->cs_gpio.port, g_lis2dh12_dev->cs_gpio.pin, 1);
    LOG_DBG("LIS2DH READ: CS set high (deselected), SPI transaction complete");

    if (ret < 0)
    {
        LOG_ERR("SPI read failed: %d", ret);
        return ret;
    }

    LOG_DBG("LIS2DH READ: raw rx_buf[0]=0x%02X, rx_buf[1]=0x%02X", rx_buf[0], rx_buf[1]);

    /* Copy received data (skip first byte which is the register echo) */
    memcpy(data, &rx_buf[1], len);

    LOG_DBG("LIS2DH READ: received data[0]=0x%02X", data[0]);
    return 0;
}

/**
 * @brief Platform-specific SPI write function for STMicroelectronics library
 *
 * This function implements the required interface for the library's function pointers.
 */
int32_t lis2dh12_platform_write(void *handle, uint8_t reg, const uint8_t *data, uint16_t len)
{
    if (!g_lis2dh12_dev || !g_lis2dh12_dev->initialized)
    {
        LOG_ERR("LIS2DH12 device not initialized");
        return -ENODEV;
    }

    /* For SPI, clear read bit (bit 7) and set increment bit (bit 6) for multi-byte writes */
    uint8_t tx_reg = reg & 0x7F; /* Clear read bit */
    if (len > 1)
    {
        tx_reg |= 0x40; /* Set increment bit for multi-byte writes */
    }

    uint8_t tx_buf[1 + len]; /* Register + data */
    tx_buf[0] = tx_reg;
    memcpy(&tx_buf[1], data, len);

    const struct spi_buf tx_bufs = {
        .buf = tx_buf,
        .len = sizeof(tx_buf)};
    const struct spi_buf_set tx = {
        .buffers = &tx_bufs,
        .count = 1};

    /* Set CS low (select device - CS is active low) */
    gpio_pin_set(g_lis2dh12_dev->cs_gpio.port, g_lis2dh12_dev->cs_gpio.pin, 0);
    k_sleep(K_USEC(10)); // Small delay for CS setup

    /* Perform SPI transaction */
    int ret = spi_write(g_lis2dh12_dev->spi_dev, &g_lis2dh12_dev->spi_cfg, &tx);

    /* Set CS high (deselect device - CS is active low) */
    gpio_pin_set(g_lis2dh12_dev->cs_gpio.port, g_lis2dh12_dev->cs_gpio.pin, 1);

    if (ret < 0)
    {
        LOG_ERR("SPI write failed: %d", ret);
        return ret;
    }

    return 0;
}

int lis2dh12_zephyr_init(struct lis2dh12_zephyr_dev *dev)
{
    if (!dev)
    {
        return -EINVAL;
    }

    LOG_INF("LIS2DH: Starting initialization...");

    /* Initialize SPI device */
    if (!device_is_ready(dev->spi_dev))
    {
        LOG_ERR("SPI device not ready");
        return -ENODEV;
    }
    LOG_INF("LIS2DH: SPI device ready");

    /* Initialize CS GPIO */
    if (!device_is_ready(dev->cs_gpio.port))
    {
        LOG_ERR("CS GPIO not ready");
        return -ENODEV;
    }
    LOG_INF("LIS2DH: CS GPIO ready (port=%p, pin=%d)", dev->cs_gpio.port, dev->cs_gpio.pin);

    /* Configure CS as output - since device tree shows GPIO_ACTIVE_LOW, we need to set it HIGH to deselect */
    int ret = gpio_pin_configure(dev->cs_gpio.port, dev->cs_gpio.pin, GPIO_OUTPUT);
    if (ret < 0)
    {
        LOG_ERR("Failed to configure CS GPIO: %d", ret);
        return ret;
    }
    LOG_INF("LIS2DH: CS GPIO configured");

    /* Set CS high initially (deselect device since CS is active low) */
    gpio_pin_set(dev->cs_gpio.port, dev->cs_gpio.pin, 1);
    LOG_INF("LIS2DH: CS set high initially (deselected)");

    /* Configure SPI for LIS2DH12 */
    dev->spi_cfg.frequency = 8000000;                            /* 8MHz max for LIS2DH12 */
    dev->spi_cfg.operation = SPI_WORD_SET(8) | SPI_TRANSFER_MSB; /* Mode 0 (CPOL=0, CPHA=0) */
    dev->spi_cfg.slave = 1;                                      /* Use slave 1 (accel@1 in device tree) */
    dev->spi_cfg.cs.delay = 0;
    LOG_INF("LIS2DH: SPI configured: freq=%d Hz, slave=%d, mode=0 (CPOL=0,CPHA=0)",
            dev->spi_cfg.frequency, dev->spi_cfg.slave);
    LOG_DBG("LIS2DH: SPI operation=0x%08X", dev->spi_cfg.operation);

    /* Set global context for platform functions */
    g_lis2dh12_dev = dev;
    dev->initialized = true;

    /* Initialize LIS2DH12 context */
    dev->ctx.handle = dev;
    dev->ctx.write_reg = (stmdev_write_ptr)lis2dh12_platform_write;
    dev->ctx.read_reg = (stmdev_read_ptr)lis2dh12_platform_read;
    dev->ctx.mdelay = NULL; // Not needed for SPI

    /* Read device ID to verify communication */
    uint8_t device_id;
    LOG_INF("LIS2DH: Attempting to read device ID...");
    ret = lis2dh12_device_id_get(&dev->ctx, &device_id);
    if (ret < 0)
    {
        LOG_ERR("Failed to read device ID: %d", ret);
        return ret;
    }

    LOG_INF("LIS2DH: Raw device ID read: 0x%02X", device_id);

    if (device_id != 0x33)
    { // LIS2DH12 device ID
        LOG_ERR("Invalid device ID: 0x%02X (expected 0x33)", device_id);
        return -ENODEV;
    }

    LOG_INF("LIS2DH12 device ID: 0x%02X", device_id);

    /* Configure basic settings */
    ret = lis2dh12_operating_mode_set(&dev->ctx, LIS2DH12_HR_12bit);
    if (ret < 0)
    {
        LOG_ERR("Failed to set power mode: %d", ret);
        return ret;
    }

    ret = lis2dh12_data_rate_set(&dev->ctx, LIS2DH12_ODR_10Hz);
    if (ret < 0)
    {
        LOG_ERR("Failed to set data rate: %d", ret);
        return ret;
    }

    ret = lis2dh12_full_scale_set(&dev->ctx, LIS2DH12_2g);
    if (ret < 0)
    {
        LOG_ERR("Failed to set full scale: %d", ret);
        return ret;
    }

    ret = lis2dh12_block_data_update_set(&dev->ctx, 1);
    if (ret < 0)
    {
        LOG_ERR("Failed to set block data update: %d", ret);
        return ret;
    }

    dev->initialized = true;
    LOG_INF("LIS2DH12 initialized successfully");

    return 0;
}

int lis2dh12_zephyr_read_accel(struct lis2dh12_zephyr_dev *dev, float *x, float *y, float *z)
{
    if (!dev || !dev->initialized || !x || !y || !z)
    {
        return -EINVAL;
    }

    int16_t raw_data[3];
    int ret = lis2dh12_acceleration_raw_get(&dev->ctx, raw_data);
    if (ret < 0)
    {
        LOG_ERR("Failed to read acceleration: %d", ret);
        return ret;
    }

    /* Convert to mg using the library function */
    *x = lis2dh12_from_fs2_hr_to_mg(raw_data[0]);
    *y = lis2dh12_from_fs2_hr_to_mg(raw_data[1]);
    *z = lis2dh12_from_fs2_hr_to_mg(raw_data[2]);

    return 0;
}

int lis2dh12_zephyr_configure_motion_detection(struct lis2dh12_zephyr_dev *dev,
                                               uint8_t threshold, uint8_t duration)
{
    if (!dev || !dev->initialized)
    {
        return -EINVAL;
    }

    int ret;

    /* Configure INT1 for motion detection */
    lis2dh12_int1_cfg_t int1_cfg = {0};
    int1_cfg.xhie = 1; // Enable X high interrupt
    int1_cfg.yhie = 1; // Enable Y high interrupt
    int1_cfg.zhie = 1; // Enable Z high interrupt
    int1_cfg.aoi = 0;  // OR combination (any axis)

    ret = lis2dh12_int1_gen_conf_set(&dev->ctx, &int1_cfg);
    if (ret < 0)
    {
        LOG_ERR("Failed to configure INT1: %d", ret);
        return ret;
    }

    /* Set motion threshold */
    ret = lis2dh12_int1_gen_threshold_set(&dev->ctx, threshold);
    if (ret < 0)
    {
        LOG_ERR("Failed to set motion threshold: %d", ret);
        return ret;
    }

    /* Set motion duration */
    ret = lis2dh12_int1_gen_duration_set(&dev->ctx, duration);
    if (ret < 0)
    {
        LOG_ERR("Failed to set motion duration: %d", ret);
        return ret;
    }

    /* Configure INT1 pin */
    lis2dh12_ctrl_reg3_t ctrl_reg3 = {0};
    ctrl_reg3.i1_ia1 = 1; // Route INT1 interrupt to INT1 pin

    ret = lis2dh12_pin_int1_config_set(&dev->ctx, &ctrl_reg3);
    if (ret < 0)
    {
        LOG_ERR("Failed to configure INT1 pin: %d", ret);
        return ret;
    }

    LOG_INF("Motion detection configured: threshold=%d, duration=%d", threshold, duration);
    return 0;
}

int lis2dh12_zephyr_read_device_id(struct lis2dh12_zephyr_dev *dev, uint8_t *id)
{
    if (!dev || !dev->initialized || !id)
    {
        return -EINVAL;
    }

    return lis2dh12_device_id_get(&dev->ctx, id);
}

bool lis2dh12_zephyr_is_ready(struct lis2dh12_zephyr_dev *dev)
{
    return dev && dev->initialized;
}
```

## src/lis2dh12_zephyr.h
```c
/*
 * Custom LIS2DH12 Zephyr Wrapper
 *
 * Copyright (c) 2024 NeurotechHub
 * SPDX-License-Identifier: Apache-2.0
 */

#ifndef LIS2DH12_ZEPHYR_H
#define LIS2DH12_ZEPHYR_H

#include <zephyr/kernel.h>
#include <zephyr/drivers/spi.h>
#include <zephyr/drivers/gpio.h>
#include <zephyr/logging/log.h>
#include "lis2dh12_reg.h"

/* LIS2DH12 device context */
struct lis2dh12_zephyr_dev
{
    const struct device *spi_dev;
    struct spi_config spi_cfg;
    struct gpio_dt_spec cs_gpio;
    struct gpio_dt_spec int_gpio;
    stmdev_ctx_t ctx;
    bool initialized;
};

/* Function prototypes */
int lis2dh12_zephyr_init(struct lis2dh12_zephyr_dev *dev);
int lis2dh12_zephyr_read_accel(struct lis2dh12_zephyr_dev *dev, float *x, float *y, float *z);
int lis2dh12_zephyr_configure_motion_detection(struct lis2dh12_zephyr_dev *dev,
                                               uint8_t threshold, uint8_t duration);
int lis2dh12_zephyr_read_device_id(struct lis2dh12_zephyr_dev *dev, uint8_t *id);
bool lis2dh12_zephyr_is_ready(struct lis2dh12_zephyr_dev *dev);

#endif /* LIS2DH12_ZEPHYR_H */
```
